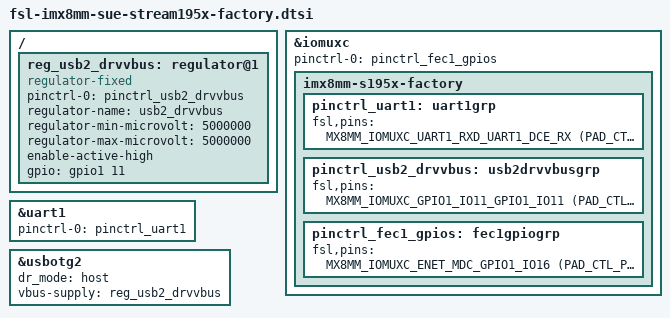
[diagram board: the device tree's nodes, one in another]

/ {
	reg_usb2_drvvbus: regulator@1 {
		compatible = "regulator-fixed";
		pinctrl-names = "default";
		pinctrl-0 = <&pinctrl_usb2_drvvbus>;

		regulator-name = "usb2_drvvbus";
		regulator-min-microvolt = <5000000>;
		regulator-max-microvolt = <5000000>;
		enable-active-high;
		gpio = <&gpio1 11 GPIO_ACTIVE_HIGH>;
	};
};

&iomuxc {
	pinctrl-names = "default";
	pinctrl-0 = <&pinctrl_fec1_gpios>;

	imx8mm-s195x-factory {
		pinctrl_uart1: uart1grp {
			fsl,pins = <
				MX8MM_IOMUXC_UART1_RXD_UART1_DCE_RX	(PAD_CTL_PE_DOWN | PAD_CTL_HYS)
				MX8MM_IOMUXC_UART1_TXD_UART1_DCE_TX	(PAD_CTL_PE_DOWN | PAD_CTL_HYS)
			>;
		};

		pinctrl_usb2_drvvbus: usb2drvvbusgrp {
			fsl,pins = <
				MX8MM_IOMUXC_GPIO1_IO11_GPIO1_IO11	(PAD_CTL_PE_DOWN | PAD_CTL_HYS)
			>;
		};

		/*
		 * Because the U-Boot will configure the pins for ethernet, we need to set
		 * them back as GPIOs, so they can be used again for the factory-tester.
		 */
		pinctrl_fec1_gpios: fec1gpiogrp {
			fsl,pins = <
				MX8MM_IOMUXC_ENET_MDC_GPIO1_IO16	(PAD_CTL_PE_DOWN | PAD_CTL_HYS)
				MX8MM_IOMUXC_ENET_MDIO_GPIO1_IO17	(PAD_CTL_PE_DOWN | PAD_CTL_HYS)
				MX8MM_IOMUXC_ENET_TD2_GPIO1_IO19	(PAD_CTL_PE_DOWN | PAD_CTL_HYS)
				MX8MM_IOMUXC_ENET_TD1_GPIO1_IO20	(PAD_CTL_PE_DOWN | PAD_CTL_HYS)
				MX8MM_IOMUXC_ENET_TD0_GPIO1_IO21	(PAD_CTL_PE_DOWN | PAD_CTL_HYS)
				MX8MM_IOMUXC_ENET_TX_CTL_GPIO1_IO22	(PAD_CTL_PE_DOWN | PAD_CTL_HYS)
				MX8MM_IOMUXC_ENET_RX_CTL_GPIO1_IO24	(PAD_CTL_PE_DOWN | PAD_CTL_HYS)
				MX8MM_IOMUXC_ENET_RXC_GPIO1_IO25	(PAD_CTL_PE_DOWN | PAD_CTL_HYS)
				MX8MM_IOMUXC_ENET_RD0_GPIO1_IO26	(PAD_CTL_PE_DOWN | PAD_CTL_HYS)
				MX8MM_IOMUXC_ENET_RD1_GPIO1_IO27	(PAD_CTL_PE_DOWN | PAD_CTL_HYS)
			>;
		};
	};
};

&uart1 {
	pinctrl-names = "default";
	pinctrl-0 = <&pinctrl_uart1>;
	status = "okay";
};

&usbotg2 {
	dr_mode = "host";
	status = "okay";
	vbus-supply = <&reg_usb2_drvvbus>;
};

